# HDSC_HC32L073PATA register map
Vendor: HDSC Co.Ltd; Series: ARMCM0P; File version: 1.2
CPU: CM0 r0p0, little endian, no MPU, no FPU, 3 interrupt priority bits
Registers are 32-bit, read-write, reset 0x0 unless marked. A register's access mark holds for its fields unless they carry their own. Offsets are from the block's base; lines under a group give offsets from that group; [hi:lo] are bit positions; {n}, {i} and the like mark numbered series; 'fields as' and 'values as' point back to an identical list; <NAME> marks a mode.

## Memory map
0x40000000 UART0 size 0x1C — desc UART
0x40000100 UART1 size 0x1C — desc UART
0x40000200 LPUART0 size 0x1C — desc LPUART
0x40000400 I2C0 size 0x18 — desc I2C
0x40000800 SPI0 size 0x18 — desc SPI
0x40000C00 TIM0_MODE0 size 0x34
0x40000C00 TIM0_MODE1 size 0x40
0x40000C00 TIM0_MODE23 size 0x44
0x40000D00 TIM1_MODE0 size 0x34
0x40000D00 TIM1_MODE1 size 0x40
0x40000D00 TIM1_MODE23 size 0x44
0x40000E00 TIM2_MODE0 size 0x34
0x40000E00 TIM2_MODE1 size 0x40
0x40000E00 TIM2_MODE23 size 0x44
0x40000F00 LPTIMER0 size 0x18 — desc LPTIMER
0x40000F00 WDT size 0x88
0x40000F40 LPTIMER1 size 0x18 — desc LPTIMER
0x40001000 PCA size 0x6C
0x40001400 RTC size 0x38
0x40001800 CLK_TRIM size 0x1C
0x40002000 SYSCTRL size 0x5C
0x4000201C RESET size 0x10
0x40002038 DEBUG_ACTIVE size 0x4
0x40002400 ADC size 0xD0
0x40002400 BGR size 0x4
0x40002400 LVD size 0x30
0x40002400 OPA size 0x40
0x40002400 VC size 0x158
0x40002500 DAC size 0x3C
0x40002800 I2S0 size 0x30 — desc I2S
0x40002C00 I2S1 size 0x30 — desc I2S
0x40003000 ADTIM4 size 0x400 — desc ADTIM
0x40003400 ADTIM5 size 0x400 — desc ADTIM
0x40003800 ADTIM6 size 0x400 — desc ADTIM
0x40004000 LPUART1 size 0x1C — desc LPUART
0x40004400 I2C1 size 0x18 — desc I2C
0x40004800 SPI1 size 0x18 — desc SPI
0x40004C00 TRNG size 0x14
0x40005000 CTS size 0x10
0x40005400 PCNT size 0x38
0x40005800 TIM3_MODE0 size 0x34
0x40005800 TIM3_MODE1 size 0x40
0x40005800 TIM3_MODE23 size 0x54
0x40005C00 LCD size 0x80
0x40006000 UART2 size 0x1C — desc UART
0x40006400 UART3 size 0x1C — desc UART
0x40020000 FLASH size 0x38
0x40020400 RAM size 0x10
0x40020900 CRC size 0x100
0x40020C00 GPIO size 0x1250
0x40021000 DMAC size 0x30
0x40021400 AES size 0x40
0x40021800 HDIV size 0x18
0x40030000 CAN size 0xCA
0x40040000 USBFS size 0xE04

## ADC
Base 0x40002400
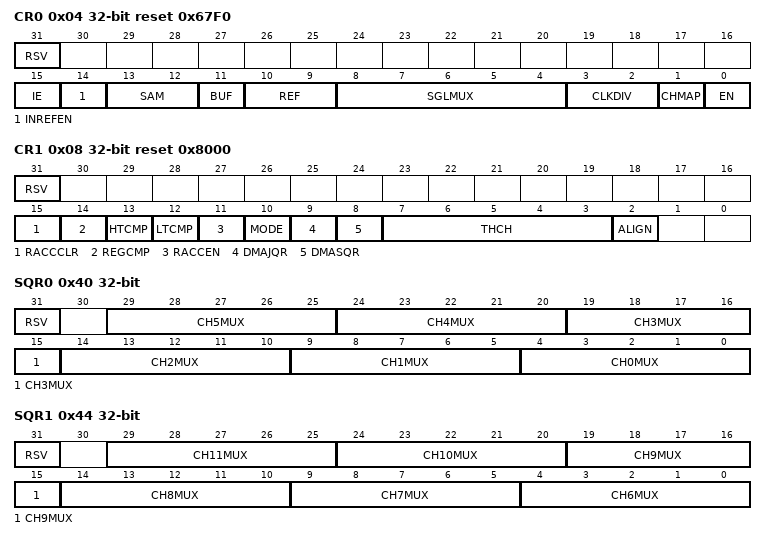
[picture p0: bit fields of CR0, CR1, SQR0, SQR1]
0x04 CR0 reset 0x67F0 (reset mask 0xBFFF)
  [31] RSV, [15] IE, [14] INREFEN, [13:12] SAM, [11] BUF, [10:9] REF, [8:4] SGLMUX, [3:2] CLKDIV, [1] CHMAP, [0] EN
0x08 CR1 reset 0x8000 (reset mask 0xFFFC)
  [31] RSV, [15] RACCCLR, [14] REGCMP, [13] HTCMP, [12] LTCMP, [11] RACCEN, [10] MODE, [9] DMAJQR, [8] DMASQR, [7:3] THCH, [2] ALIGN
0x40 SQR0 (reset mask 0x3FFFFFFF)
  [31] RSV, [5n+4:5n] CH{n}MUX (n=0..5)
0x44 SQR1 (reset mask 0x3FFFFFFF)
  [31] RSV, [5n-26:5n-30] CH{n}MUX (n=6..11)
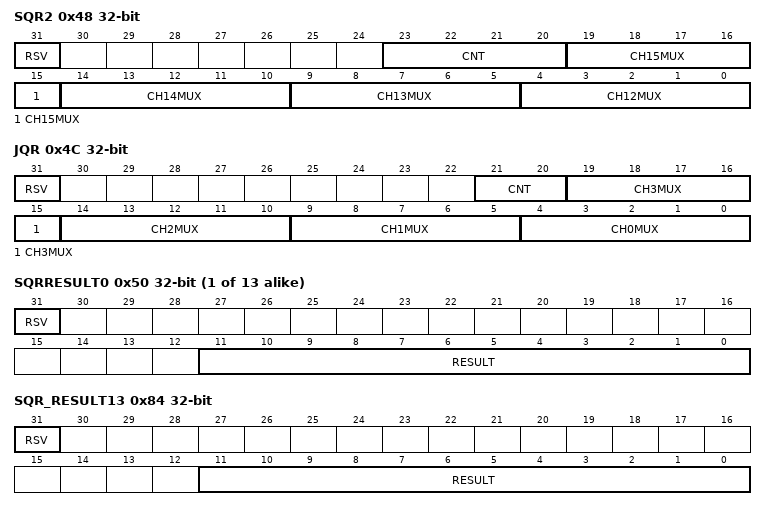
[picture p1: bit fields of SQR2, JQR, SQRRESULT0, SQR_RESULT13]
0x48 SQR2 (reset mask 0xFFFFFFF)
  [31] RSV, [23:20] CNT, [5n-56:5n-60] CH{n}MUX (n=12..15)
0x4C JQR (reset mask 0x3FFFFFF)
  [31] RSV, [21:20] CNT, [5n+4:5n] CH{n}MUX (n=0..3)
{0x50+4i} SQRRESULT{i} ro (reset mask 0xFFF) (i=0..12)
  [31] RSV rw, [11:0] RESULT
0x84 SQR_RESULT13 ro (reset mask 0xFFF)
  [31] RSV rw, [11:0] RESULT
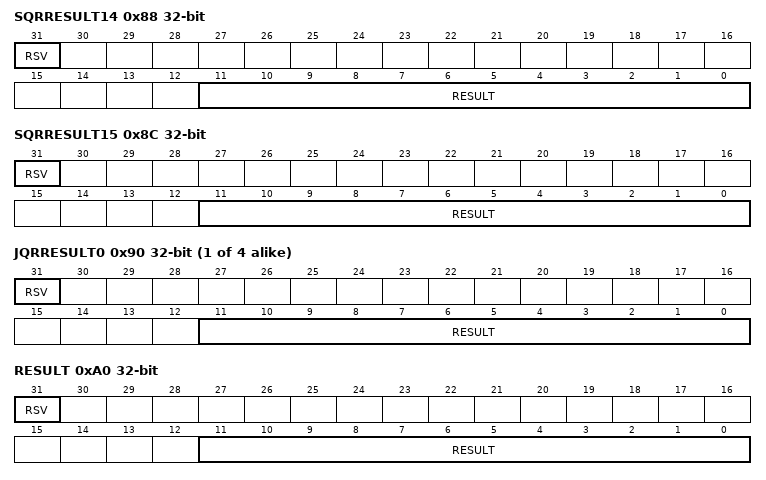
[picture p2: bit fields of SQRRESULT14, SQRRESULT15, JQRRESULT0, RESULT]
0x88 SQRRESULT14 ro (reset mask 0xFFF)
  [31] RSV rw, [11:0] RESULT
0x8C SQRRESULT15 ro (reset mask 0xFFF)
  [31] RSV rw, [11:0] RESULT
{0x90+4i} JQRRESULT{i} ro (reset mask 0xFFF) (i=0..3)
  [31] RSV rw, [11:0] RESULT
0xA0 RESULT ro (reset mask 0xFFF)
  [31] RSV rw, [11:0] RESULT
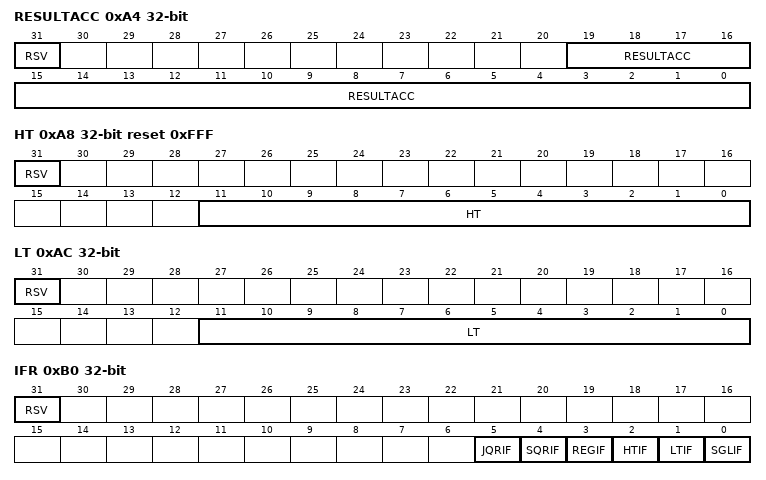
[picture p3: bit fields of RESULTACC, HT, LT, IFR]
0xA4 RESULTACC ro (reset mask 0xFFFFF)
  [31] RSV rw, [19:0] RESULTACC
0xA8 HT reset 0xFFF (reset mask 0xFFF)
  [31] RSV, [11:0] HT
0xAC LT (reset mask 0xFFF)
  [31] RSV, [11:0] LT
0xB0 IFR ro (reset mask 0x3F)
  [31] RSV rw, [5] JQRIF, [4] SQRIF, [3] REGIF, [2] HTIF, [1] LTIF, [0] SGLIF
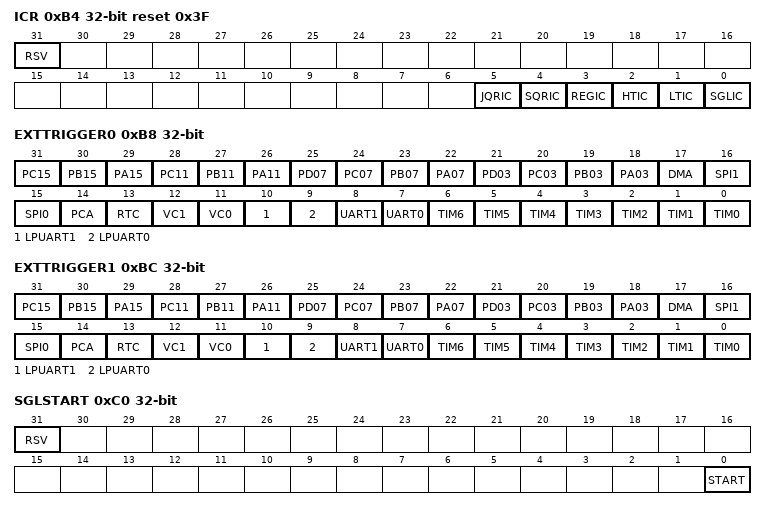
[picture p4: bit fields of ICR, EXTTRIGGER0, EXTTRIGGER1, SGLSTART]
0xB4 ICR wo reset 0x3F (reset mask 0x3F)
  [31] RSV rw, [5] JQRIC, [4] SQRIC, [3] REGIC, [2] HTIC, [1] LTIC, [0] SGLIC
0xB8 EXTTRIGGER0
  [31] PC15, [30] PB15, [29] PA15, [28] PC11, [27] PB11, [26] PA11, [25] PD07, [24] PC07, [23] PB07, [22] PA07, [21] PD03, [20] PC03, [19] PB03, [18] PA03, [17] DMA, [16] SPI1, [15] SPI0, [14] PCA, [13] RTC, [12] VC1, [11] VC0, [10] LPUART1, [9] LPUART0, [8] UART1, [7] UART0, [n] TIM{n} (n=0..6)
0xBC EXTTRIGGER1
  fields as EXTTRIGGER0
0xC0 SGLSTART (reset mask 0x1)
  [31] RSV, [0] START
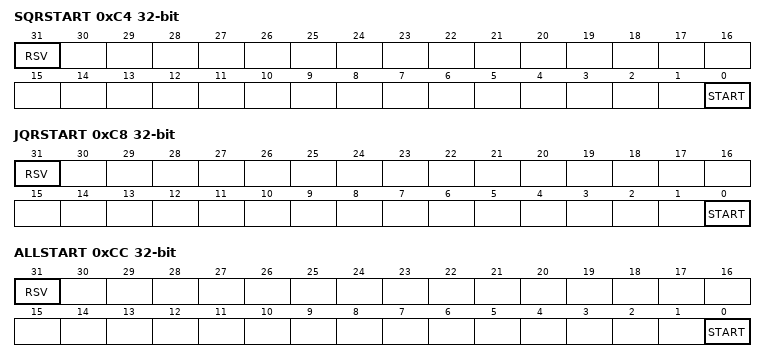
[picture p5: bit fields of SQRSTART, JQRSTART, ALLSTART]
0xC4 SQRSTART (reset mask 0x1)
  [31] RSV, [0] START
0xC8 JQRSTART (reset mask 0x1)
  [31] RSV, [0] START
0xCC ALLSTART (reset mask 0x1)
  [31] RSV, [0] START
